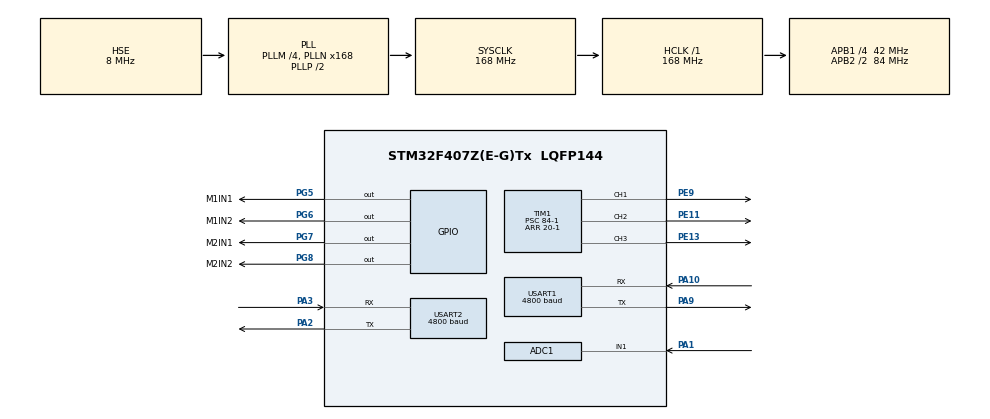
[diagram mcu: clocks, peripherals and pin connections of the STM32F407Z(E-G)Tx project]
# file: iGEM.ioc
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ADC1.Channel-0\#ChannelRegularConversion=ADC_CHANNEL_1
ADC1.NbrOfConversionFlag=1
ADC1.Rank-0\#ChannelRegularConversion=1
ADC1.SamplingTime-0\#ChannelRegularConversion=ADC_SAMPLETIME_3CYCLES
ADC1.master=1
FREERTOS.INCLUDE_vTaskDelayUntil=1
FREERTOS.Queues01=PHQueue,3,float,0,Dynamic,NULL,NULL;DOCQueue,3,float,0,Dynamic,NULL,NULL;oContentQueue,3,float,0,Dynamic,NULL,NULL
FREERTOS.Tasks01=basicTask,2,128,BasicTask,As weak,NULL,Dynamic,NULL,NULL
FREERTOS.configENABLE_FPU=1
FREERTOS.configUSE_NEWLIB_REENTRANT=1
Mcu.Family=STM32F4
Mcu.Name=STM32F407Z(E-G)Tx
Mcu.Package=LQFP144
NVIC.PriorityGroup=NVIC_PRIORITYGROUP_4
NVIC.TIM4_IRQn=true\:15\:0\:false\:false\:true\:false\:false\:true\:true
NVIC.TimeBase=TIM4_IRQn
NVIC.TimeBaseIP=TIM4
NVIC.USART1_IRQn=true\:5\:0\:false\:false\:true\:true\:true\:true\:true
NVIC.USART2_IRQn=true\:5\:0\:false\:false\:true\:true\:true\:true\:true
PA0-WKUP.Mode=SYS_WakeUp0
PA0-WKUP.Signal=SYS_WKUP
PA1.Signal=ADCx_IN1
PA10.Mode=Asynchronous
PA10.Signal=USART1_RX
PA13.Mode=Trace_Asynchronous_SW
PA13.Signal=SYS_JTMS-SWDIO
PA14.Mode=Trace_Asynchronous_SW
PA14.Signal=SYS_JTCK-SWCLK
PA2.Mode=Asynchronous
PA2.Signal=USART2_TX
PA3.Mode=Asynchronous
PA3.Signal=USART2_RX
PA9.Mode=Asynchronous
PA9.Signal=USART1_TX
PB3.Mode=Trace_Asynchronous_SW
PB3.Signal=SYS_JTDO-SWO
PC14-OSC32_IN.Mode=LSE-External-Clock-Source
PC14-OSC32_IN.Signal=RCC_OSC32_IN
PC15-OSC32_OUT.Mode=LSE-External-Clock-Source
PC15-OSC32_OUT.Signal=RCC_OSC32_OUT
PE11.Signal=S_TIM1_CH2
PE13.Signal=S_TIM1_CH3
PE9.Signal=S_TIM1_CH1
PG5.GPIO_Label=M1IN1
PG5.GPIO_PuPd=GPIO_PULLDOWN
PG5.GPIO_Speed=GPIO_SPEED_FREQ_HIGH
PG5.Signal=GPIO_Output
PG6.GPIO_Label=M1IN2
PG6.GPIO_PuPd=GPIO_PULLDOWN
PG6.GPIO_Speed=GPIO_SPEED_FREQ_HIGH
PG6.Signal=GPIO_Output
PG7.GPIO_Label=M2IN1
PG7.GPIO_PuPd=GPIO_PULLDOWN
PG7.GPIO_Speed=GPIO_SPEED_FREQ_HIGH
PG7.Signal=GPIO_Output
PG8.GPIO_Label=M2IN2
PG8.GPIO_PuPd=GPIO_PULLDOWN
PG8.GPIO_Speed=GPIO_SPEED_FREQ_HIGH
PG8.Signal=GPIO_Output
PH0-OSC_IN.Mode=HSE-External-Oscillator
PH0-OSC_IN.Signal=RCC_OSC_IN
PH1-OSC_OUT.Mode=HSE-External-Oscillator
PH1-OSC_OUT.Signal=RCC_OSC_OUT
ProjectManager.HeapSize=0x200
ProjectManager.StackSize=0x400
ProjectManager.TargetToolchain=STM32CubeIDE
RCC.48MHZClocksFreq_Value=84000000
RCC.AHBFreq_Value=168000000
RCC.APB1CLKDivider=RCC_HCLK_DIV4
RCC.APB1Freq_Value=42000000
RCC.APB1TimFreq_Value=84000000
RCC.APB2CLKDivider=RCC_HCLK_DIV2
RCC.APB2Freq_Value=84000000
RCC.APB2TimFreq_Value=168000000
RCC.CortexFreq_Value=168000000
RCC.HCLKFreq_Value=168000000
RCC.HSE_VALUE=8000000
RCC.HSI_VALUE=16000000
RCC.LSE_VALUE=32768
RCC.PLLM=4
RCC.PLLN=168
RCC.PLLSourceVirtual=RCC_PLLSOURCE_HSE
RCC.SYSCLKFreq_VALUE=168000000
RCC.SYSCLKSource=RCC_SYSCLKSOURCE_PLLCLK
RCC.VCOOutputFreq_Value=336000000
SH.ADCx_IN1.0=ADC1_IN1,IN1
SH.S_TIM1_CH1.0=TIM1_CH1,PWM Generation1 CH1
SH.S_TIM1_CH2.0=TIM1_CH2,PWM Generation2 CH2
SH.S_TIM1_CH3.0=TIM1_CH3,PWM Generation3 CH3
TIM1.Channel-PWM\ Generation1\ CH1=TIM_CHANNEL_1
TIM1.Channel-PWM\ Generation2\ CH2=TIM_CHANNEL_2
TIM1.Channel-PWM\ Generation3\ CH3=TIM_CHANNEL_3
TIM1.Period=20-1
TIM1.Prescaler=84-1
USART1.BaudRate=4800
USART1.VirtualMode=VM_ASYNC
USART2.BaudRate=4800
USART2.VirtualMode=VM_ASYNC
VP_ADC1_TempSens_Input.Mode=IN-TempSens
VP_ADC1_Vbat_Input.Mode=IN-Vbat
VP_ADC1_Vref_Input.Mode=IN-Vrefint
VP_CRC_VS_CRC.Mode=CRC_Activate
VP_FREERTOS_VS_CMSIS_V1.Mode=CMSIS_V1
VP_SYS_VS_tim4.Mode=TIM4
VP_TIM1_VS_ClockSourceINT.Mode=Internal
board=custom

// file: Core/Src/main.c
/* USER CODE BEGIN Header */
/**
  ******************************************************************************
  * @file           : main.c
  * @brief          : Main program body
  ******************************************************************************
  * @attention
  *
  * Copyright (c) 2023 STMicroelectronics.
  * All rights reserved.
  *
  * This software is licensed under terms that can be found in the LICENSE file
  * in the root directory of this software component.
  * If no LICENSE file comes with this software, it is provided AS-IS.
  *
  ******************************************************************************
  */
/* USER CODE END Header */
#include "main.h"
#include "cmsis_os.h"
#include "adc.h"
#include "crc.h"
#include "tim.h"
#include "usart.h"
#include "gpio.h"

/* USER CODE BEGIN Includes */
#include "rs485.h"
#include "l298n.h"
/* USER CODE END Includes */

void SystemClock_Config(void);
void MX_FREERTOS_Init(void);

int main(void)
{

  /* MCU Configuration--------------------------------------------------------*/

  /* Reset of all peripherals, Initializes the Flash interface and the Systick. */
  HAL_Init();

  /* Configure the system clock */
  SystemClock_Config();

  /* Initialize all configured peripherals */
  MX_GPIO_Init();
  MX_USART1_UART_Init();
  MX_USART2_UART_Init();
  MX_TIM1_Init();
  MX_CRC_Init();
  MX_ADC1_Init();
  /* USER CODE BEGIN 2 */
  RS485ReceiveIT_Init();
  Peristaltic_Pump_Init();
  /* USER CODE END 2 */

  /* Call init function for freertos objects (in freertos.c) */
  MX_FREERTOS_Init();

  /* Start scheduler */
  osKernelStart();

  /* We should never get here as control is now taken by the scheduler */
  /* Infinite loop */
  while (1)
  {

  }
}

void SystemClock_Config(void)
{
  RCC_OscInitTypeDef RCC_OscInitStruct = {0};
  RCC_ClkInitTypeDef RCC_ClkInitStruct = {0};

  /** Configure the main internal regulator output voltage
  */
  __HAL_RCC_PWR_CLK_ENABLE();
  __HAL_PWR_VOLTAGESCALING_CONFIG(PWR_REGULATOR_VOLTAGE_SCALE1);

  /** Initializes the RCC Oscillators according to the specified parameters
  * in the RCC_OscInitTypeDef structure.
  */
  RCC_OscInitStruct.OscillatorType = RCC_OSCILLATORTYPE_HSE;
  RCC_OscInitStruct.HSEState = RCC_HSE_ON;
  RCC_OscInitStruct.PLL.PLLState = RCC_PLL_ON;
  RCC_OscInitStruct.PLL.PLLSource = RCC_PLLSOURCE_HSE;
  RCC_OscInitStruct.PLL.PLLM = 4;
  RCC_OscInitStruct.PLL.PLLN = 168;
  RCC_OscInitStruct.PLL.PLLP = RCC_PLLP_DIV2;
  RCC_OscInitStruct.PLL.PLLQ = 4;
  if (HAL_RCC_OscConfig(&RCC_OscInitStruct) != HAL_OK)
  {
    Error_Handler();
  }

  /** Initializes the CPU, AHB and APB buses clocks
  */
  RCC_ClkInitStruct.ClockType = RCC_CLOCKTYPE_HCLK|RCC_CLOCKTYPE_SYSCLK
                              |RCC_CLOCKTYPE_PCLK1|RCC_CLOCKTYPE_PCLK2;
  RCC_ClkInitStruct.SYSCLKSource = RCC_SYSCLKSOURCE_PLLCLK;
  RCC_ClkInitStruct.AHBCLKDivider = RCC_SYSCLK_DIV1;
  RCC_ClkInitStruct.APB1CLKDivider = RCC_HCLK_DIV4;
  RCC_ClkInitStruct.APB2CLKDivider = RCC_HCLK_DIV2;

  if (HAL_RCC_ClockConfig(&RCC_ClkInitStruct, FLASH_LATENCY_5) != HAL_OK)
  {
    Error_Handler();
  }
}

void HAL_TIM_PeriodElapsedCallback(TIM_HandleTypeDef *htim)
{
  if (htim->Instance == TIM4) {
    HAL_IncTick();
  }
}

void Error_Handler(void)
{
  __disable_irq();
  while (1)
  {
  }
}

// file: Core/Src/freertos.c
/* USER CODE BEGIN Header */
/**
  ******************************************************************************
  * File Name          : freertos.c
  * Description        : Code for freertos applications
  ******************************************************************************
  * @attention
  *
  * Copyright (c) 2023 STMicroelectronics.
  * All rights reserved.
  *
  * This software is licensed under terms that can be found in the LICENSE file
  * in the root directory of this software component.
  * If no LICENSE file comes with this software, it is provided AS-IS.
  *
  ******************************************************************************
  */
/* USER CODE END Header */

#include "FreeRTOS.h"
#include "task.h"
#include "main.h"
#include "cmsis_os.h"

osThreadId basicTaskHandle;
osMessageQId PHQueueHandle;
osMessageQId DOCQueueHandle;
osMessageQId oContentQueueHandle;

void BasicTask(void const * argument);

void MX_FREERTOS_Init(void); /* (MISRA C 2004 rule 8.1) */

/* GetIdleTaskMemory prototype (linked to static allocation support) */
void vApplicationGetIdleTaskMemory( StaticTask_t **ppxIdleTaskTCBBuffer, StackType_t **ppxIdleTaskStackBuffer, uint32_t *pulIdleTaskStackSize );

/* USER CODE BEGIN GET_IDLE_TASK_MEMORY */
static StaticTask_t xIdleTaskTCBBuffer;
static StackType_t xIdleStack[configMINIMAL_STACK_SIZE];

void vApplicationGetIdleTaskMemory( StaticTask_t **ppxIdleTaskTCBBuffer, StackType_t **ppxIdleTaskStackBuffer, uint32_t *pulIdleTaskStackSize )
{
  *ppxIdleTaskTCBBuffer = &xIdleTaskTCBBuffer;
  *ppxIdleTaskStackBuffer = &xIdleStack[0];
  *pulIdleTaskStackSize = configMINIMAL_STACK_SIZE;
  /* place for user code */
}
/* USER CODE END GET_IDLE_TASK_MEMORY */

void MX_FREERTOS_Init(void) {

  /* Create the queue(s) */
  /* definition and creation of PHQueue */
  osMessageQDef(PHQueue, 3, float);
  PHQueueHandle = osMessageCreate(osMessageQ(PHQueue), NULL);

  /* definition and creation of DOCQueue */
  osMessageQDef(DOCQueue, 3, float);
  DOCQueueHandle = osMessageCreate(osMessageQ(DOCQueue), NULL);

  /* definition and creation of oContentQueue */
  osMessageQDef(oContentQueue, 3, float);
  oContentQueueHandle = osMessageCreate(osMessageQ(oContentQueue), NULL);

  /* Create the thread(s) */
  /* definition and creation of basicTask */
  osThreadDef(basicTask, BasicTask, osPriorityHigh, 0, 128);
  basicTaskHandle = osThreadCreate(osThread(basicTask), NULL);

}

__weak void BasicTask(void const * argument)
{
  for(;;)
  {
    osDelay(1);
  }
}
